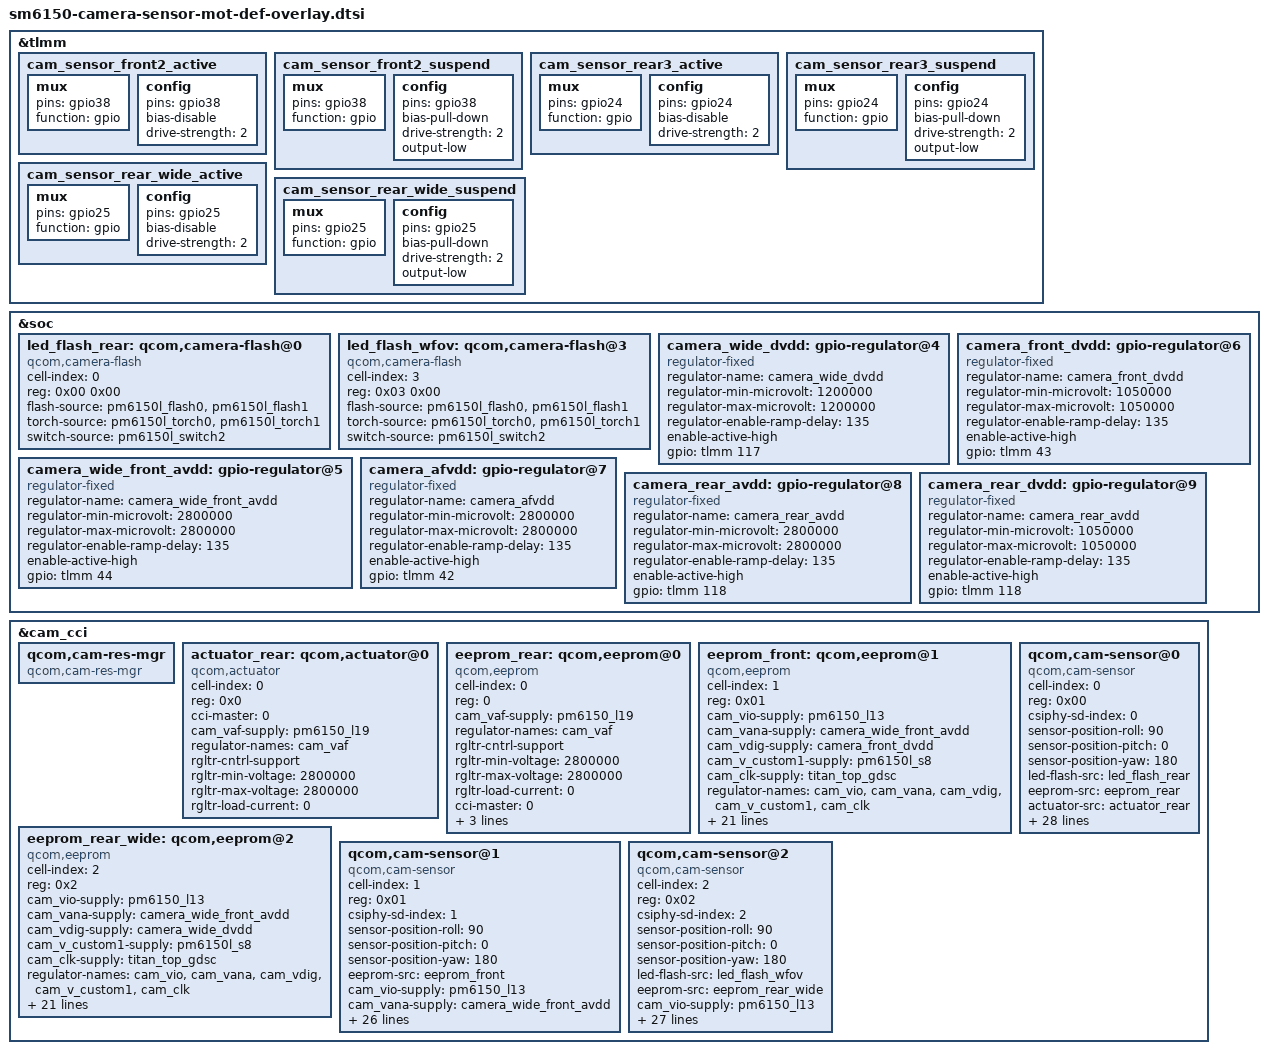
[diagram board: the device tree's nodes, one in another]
/*
 * Copyright (c) 2018, The Linux Foundation. All rights reserved.
 *
 * This program is free software; you can redistribute it and/or modify
 * it under the terms of the GNU General Public License version 2 and
 * only version 2 as published by the Free Software Foundation.
 *
 * This program is distributed in the hope that it will be useful,
 * but WITHOUT ANY WARRANTY; without even the implied warranty of
 * MERCHANTABILITY or FITNESS FOR A PARTICULAR PURPOSE.  See the
 * GNU General Public License for more details.
 */
&tlmm {
	cam_sensor_front2_active: cam_sensor_front2_active {
		/* RESET  */
		mux {
			pins = "gpio38";
			function = "gpio";
		};

		config {
			pins = "gpio38";
			bias-disable; /* No PULL */
			drive-strength = <2>; /* 2 MA */
		};
	};

	cam_sensor_front2_suspend: cam_sensor_front2_suspend {
	/* RESET */
		mux {
			pins = "gpio38";
			function = "gpio";
		};

		config {
			pins = "gpio38";
			bias-pull-down; /* PULL DOWN */
			drive-strength = <2>; /* 2 MA */
			output-low;
		};
	};


	cam_sensor_rear3_active: cam_sensor_rear3_active {
		/* RESET */
		mux {
			pins = "gpio24";
			function = "gpio";
		};

		config {
			pins = "gpio24";
			bias-disable; /* No PULL */
			drive-strength = <2>; /* 2 MA */
		};
	};

	cam_sensor_rear3_suspend: cam_sensor_rear3_suspend {
		/* RESET */
		mux {
			pins = "gpio24";
			function = "gpio";
		};

		config {
			pins = "gpio24";
			bias-pull-down; /* PULL DOWN */
			drive-strength = <2>; /* 2 MA */
			output-low;
		};
	};

	cam_sensor_rear_wide_active: cam_sensor_rear_wide_active {
		/* RESET */
		mux {
			pins = "gpio25";
			function = "gpio";
		};

		config {
			pins = "gpio25";
			bias-disable; /* No PULL */
			drive-strength = <2>; /* 2 MA */
		};
	};

	cam_sensor_rear_wide_suspend: cam_sensor_rear_wide_suspend {
		/* RESET */
		mux {
			pins = "gpio25";
			function = "gpio";
		};

		config {
			pins = "gpio25";
			bias-pull-down; /* PULL DOWN */
			drive-strength = <2>; /* 2 MA */
			output-low;
		};
	};
};

&soc {
	led_flash_rear: qcom,camera-flash@0 {
		cell-index = <0>;
		reg = <0x00 0x00>;
		compatible = "qcom,camera-flash";
		flash-source = <&pm6150l_flash0 &pm6150l_flash1>;
		torch-source = <&pm6150l_torch0 &pm6150l_torch1>;
		switch-source = <&pm6150l_switch2>;
		status = "ok";
	};

	led_flash_wfov: qcom,camera-flash@3 {
		cell-index = <3>;
		reg = <0x03 0x00>;
		compatible = "qcom,camera-flash";
		flash-source = <&pm6150l_flash0 &pm6150l_flash1>;
		torch-source = <&pm6150l_torch0 &pm6150l_torch1>;
		switch-source = <&pm6150l_switch2>;
		status = "ok";
	};

	camera_wide_dvdd: gpio-regulator@4 {
		compatible = "regulator-fixed";
		regulator-name = "camera_wide_dvdd";
		regulator-min-microvolt = <1200000>;
		regulator-max-microvolt = <1200000>;
		regulator-enable-ramp-delay = <135>;
		enable-active-high;
		gpio = <&tlmm 117 0>;
	};

	camera_wide_front_avdd: gpio-regulator@5 {
		compatible = "regulator-fixed";
		regulator-name = "camera_wide_front_avdd";
		regulator-min-microvolt = <2800000>;
		regulator-max-microvolt = <2800000>;
		regulator-enable-ramp-delay = <135>;
		enable-active-high;
		gpio = <&tlmm 44 0>;
	};

	camera_front_dvdd: gpio-regulator@6 {
		compatible = "regulator-fixed";
		regulator-name = "camera_front_dvdd";
		regulator-min-microvolt = <1050000>;
		regulator-max-microvolt = <1050000>;
		regulator-enable-ramp-delay = <135>;
		enable-active-high;
		gpio = <&tlmm 43 0>;
	};

	camera_afvdd: gpio-regulator@7 {
		compatible = "regulator-fixed";
		regulator-name = "camera_afvdd";
		regulator-min-microvolt = <2800000>;
		regulator-max-microvolt = <2800000>;
		regulator-enable-ramp-delay = <135>;
		enable-active-high;
		gpio = <&tlmm 42 0>;
	};

	camera_rear_avdd: gpio-regulator@8 {
		compatible = "regulator-fixed";
		regulator-name = "camera_rear_avdd";
		regulator-min-microvolt = <2800000>;
		regulator-max-microvolt = <2800000>;
		regulator-enable-ramp-delay = <135>;
		enable-active-high;
		gpio = <&tlmm 118 0>;
	};

	camera_rear_dvdd: gpio-regulator@9 {
		compatible = "regulator-fixed";
		regulator-name = "camera_rear_avdd";
		regulator-min-microvolt = <1050000>;
		regulator-max-microvolt = <1050000>;
		regulator-enable-ramp-delay = <135>;
		enable-active-high;
		gpio = <&tlmm 118 0>;
	};

};

&cam_cci {
	qcom,cam-res-mgr {
		compatible = "qcom,cam-res-mgr";
		status = "ok";
	};

	actuator_rear: qcom,actuator@0 {
		cell-index = <0>;
		reg = <0x0>;
		compatible = "qcom,actuator";
		cci-master = <0>;
		cam_vaf-supply = <&pm6150_l19>;
		regulator-names = "cam_vaf";
		rgltr-cntrl-support;
		rgltr-min-voltage = <2800000>;
		rgltr-max-voltage = <2800000>;
		rgltr-load-current = <0>;
	};

	eeprom_rear: qcom,eeprom@0 {
		cell-index = <0>;
		reg = <0>;
		compatible = "qcom,eeprom";
		cam_vaf-supply = <&pm6150_l19>;
		regulator-names = "cam_vaf";
		rgltr-cntrl-support;
		rgltr-min-voltage = <2800000>;
		rgltr-max-voltage = <2800000>;
		rgltr-load-current = <0>;
		cci-master = <0>;
		status = "ok";
		clocks = <&clock_camcc CAM_CC_MCLK2_CLK>;
		clock-names = "cam_clk";
		clock-cntl-level = "turbo";
		clock-rates = <24000000>;
	};

	eeprom_front: qcom,eeprom@1 {
		cell-index = <1>;
		reg = <0x01>;
		compatible = "qcom,eeprom";
		cam_vio-supply = <&pm6150_l13>;
		cam_vana-supply = <&camera_wide_front_avdd>;
		cam_vdig-supply = <&camera_front_dvdd>;
		cam_v_custom1-supply = <&pm6150l_s8>;
		cam_clk-supply = <&titan_top_gdsc>;
		regulator-names = "cam_vio", "cam_vana", "cam_vdig",
				"cam_v_custom1", "cam_clk";
		rgltr-cntrl-support;
		rgltr-min-voltage = <1800000 2800000 1050000 1350000 0>;
		rgltr-max-voltage = <1800000 2800000 1050000 1350000 0>;
		rgltr-load-current = <0 80000 105000 105000 0>;
		gpio-no-mux = <0>;
		pinctrl-names = "cam_default", "cam_suspend";
		pinctrl-0 = <&cam_sensor_mclk0_active
				&cam_sensor_front2_active>;
		pinctrl-1 = <&cam_sensor_mclk0_suspend
				&cam_sensor_front2_suspend>;
		gpios = <&tlmm 28 0>,
			<&tlmm 38 0>;
		gpio-reset = <1>;
		gpio-req-tbl-num = <0 1>;
		gpio-req-tbl-flags = <1 0>;
		gpio-req-tbl-label = "CAMIF_MCLK0",
				"CAM_RESET1";
		sensor-mode = <0>;
		cci-master = <1>;
		status = "ok";
		clocks = <&clock_camcc CAM_CC_MCLK0_CLK>;
		clock-names = "cam_clk";
		clock-cntl-level = "turbo";
		clock-rates = <24000000>;
	};

	eeprom_rear_wide: qcom,eeprom@2 {
		cell-index = <2>;
		reg = <0x2>;
		compatible = "qcom,eeprom";
		cam_vio-supply = <&pm6150_l13>;
		cam_vana-supply = <&camera_wide_front_avdd>;
		cam_vdig-supply = <&camera_wide_dvdd>;
		cam_v_custom1-supply = <&pm6150l_s8>;
		cam_clk-supply = <&titan_top_gdsc>;
		regulator-names = "cam_vio", "cam_vana", "cam_vdig",
				"cam_v_custom1", "cam_clk";
		rgltr-cntrl-support;
		rgltr-min-voltage = <1800000 2800000 1200000 1350000 0>;
		rgltr-max-voltage = <1800000 2800000 1200000 1350000 0>;
		rgltr-load-current = <0 80000 105000 105000 0>;
		gpio-no-mux = <0>;
		pinctrl-names = "cam_default", "cam_suspend";
		pinctrl-0 = <&cam_sensor_mclk1_active
				&cam_sensor_rear_wide_active>;
		pinctrl-1 = <&cam_sensor_mclk1_suspend
				&cam_sensor_rear_wide_suspend>;
		gpios = <&tlmm 29 0>,
			<&tlmm 25 0>;
		gpio-reset = <1>;
		gpio-req-tbl-num = <0 1>;
		gpio-req-tbl-flags = <1 0>;
		gpio-req-tbl-label = "CAMIF_MCLK1",
				"CAM_RESET2";
		sensor-mode = <0>;
		cci-master = <1>;
		status = "ok";
		clocks = <&clock_camcc CAM_CC_MCLK1_CLK>;
		clock-names = "cam_clk";
		clock-cntl-level = "turbo";
		clock-rates = <24000000>;
	};

	qcom,cam-sensor@0 {
		cell-index = <0>;
		compatible = "qcom,cam-sensor";
		reg = <0x00>;
		csiphy-sd-index = <0>;
		sensor-position-roll = <90>;
		sensor-position-pitch = <0>;
		sensor-position-yaw = <180>;
		led-flash-src = <&led_flash_rear>;
		eeprom-src = <&eeprom_rear>;
		actuator-src = <&actuator_rear>;
		cam_vio-supply = <&pm6150_l13>;
		cam_vana-supply = <&camera_rear_avdd>;
		cam_vdig-supply = <&camera_rear_dvdd>;
		cam_v_custom1-supply = <&pm6150l_s8>;
		cam_clk-supply = <&titan_top_gdsc>;
		regulator-names = "cam_vio", "cam_vana", "cam_vdig",
				"cam_v_custom1", "cam_clk";
		rgltr-cntrl-support;
		rgltr-min-voltage = <1800000 2800000 1050000 1350000 0>;
		rgltr-max-voltage = <1800000 2800000 1050000 1350000 0>;
		rgltr-load-current = <0 80000 105000 105000 0>;
		gpio-no-mux = <0>;
		pinctrl-names = "cam_default", "cam_suspend";
		pinctrl-0 = <&cam_sensor_mclk2_active
				&cam_sensor_rear3_active>;
		pinctrl-1 = <&cam_sensor_mclk2_suspend
				&cam_sensor_rear3_suspend>;
		gpios = <&tlmm 30 0>,
			<&tlmm 24 0>;
		gpio-reset = <1>;
		gpio-req-tbl-num = <0 1>;
		gpio-req-tbl-flags = <1 0>;
		gpio-req-tbl-label = "CAMIF_MCLK2",
				"CAM_RESET1";
		sensor-mode = <0>;
		cci-master = <0>;
		status = "ok";
		clocks = <&clock_camcc CAM_CC_MCLK2_CLK>;
		clock-names = "cam_clk";
		clock-cntl-level = "turbo";
		clock-rates = <24000000>;
	};

	qcom,cam-sensor@1 {
		cell-index = <1>;
		compatible = "qcom,cam-sensor";
		reg = <0x01>;
		csiphy-sd-index = <1>;
		sensor-position-roll = <90>;
		sensor-position-pitch = <0>;
		sensor-position-yaw = <180>;
		eeprom-src = <&eeprom_front>;
		cam_vio-supply = <&pm6150_l13>;
		cam_vana-supply = <&camera_wide_front_avdd>;
		cam_vdig-supply = <&camera_front_dvdd>;
		cam_v_custom1-supply = <&pm6150l_s8>;
		cam_clk-supply = <&titan_top_gdsc>;
		regulator-names = "cam_vio", "cam_vana", "cam_vdig",
				"cam_v_custom1", "cam_clk";
		rgltr-cntrl-support;
		rgltr-min-voltage = <1800000 2800000 1050000 1350000 0>;
		rgltr-max-voltage = <1800000 2800000 1050000 1350000 0>;
		rgltr-load-current = <0 80000 105000 105000 0>;
		gpio-no-mux = <0>;
		pinctrl-names = "cam_default", "cam_suspend";
		pinctrl-0 = <&cam_sensor_mclk0_active
				&cam_sensor_front2_active>;
		pinctrl-1 = <&cam_sensor_mclk0_suspend
				&cam_sensor_front2_suspend>;
		gpios = <&tlmm 28 0>,
			<&tlmm 38 0>;
		gpio-reset = <1>;
		gpio-req-tbl-num = <0 1>;
		gpio-req-tbl-flags = <1 0>;
		gpio-req-tbl-label = "CAMIF_MCLK0",
				"CAM_RESET1";
		sensor-mode = <0>;
		cci-master = <1>;
		status = "ok";
		clocks = <&clock_camcc CAM_CC_MCLK0_CLK>;
		clock-names = "cam_clk";
		clock-cntl-level = "turbo";
		clock-rates = <24000000>;
	};

	qcom,cam-sensor@2 {
		cell-index = <2>;
		compatible = "qcom,cam-sensor";
		reg = <0x02>;
		csiphy-sd-index = <2>;
		sensor-position-roll = <90>;
		sensor-position-pitch = <0>;
		sensor-position-yaw = <180>;
		led-flash-src = <&led_flash_wfov>;
		eeprom-src = <&eeprom_rear_wide>;
		cam_vio-supply = <&pm6150_l13>;
		cam_vana-supply = <&camera_wide_front_avdd>;
		cam_vdig-supply = <&camera_wide_dvdd>;
		cam_v_custom1-supply = <&pm6150l_s8>;
		cam_clk-supply = <&titan_top_gdsc>;
		regulator-names = "cam_vio", "cam_vana", "cam_vdig",
				"cam_v_custom1", "cam_clk";
		rgltr-cntrl-support;
		rgltr-min-voltage = <1800000 2800000 1200000 1350000 0>;
		rgltr-max-voltage = <1800000 2800000 1200000 1350000 0>;
		rgltr-load-current = <0 80000 105000 105000 0>;
		gpio-no-mux = <0>;
		pinctrl-names = "cam_default", "cam_suspend";
		pinctrl-0 = <&cam_sensor_mclk1_active
				&cam_sensor_rear_wide_active>;
		pinctrl-1 = <&cam_sensor_mclk1_suspend
				&cam_sensor_rear_wide_suspend>;
		gpios = <&tlmm 29 0>,
			<&tlmm 25 0>;
		gpio-reset = <1>;
		gpio-req-tbl-num = <0 1>;
		gpio-req-tbl-flags = <1 0>;
		gpio-req-tbl-label = "CAMIF_MCLK1",
				"CAM_RESET2";
		sensor-mode = <0>;
		cci-master = <1>;
		status = "ok";
		clocks = <&clock_camcc CAM_CC_MCLK1_CLK>;
		clock-names = "cam_clk";
		clock-cntl-level = "turbo";
		clock-rates = <24000000>;
	};
};
